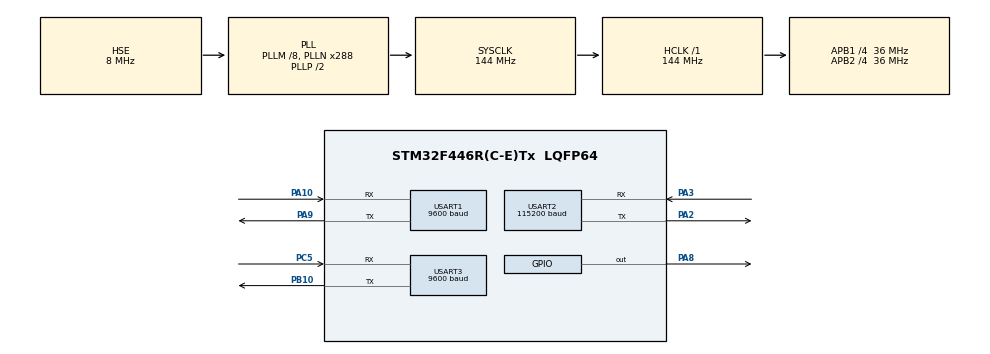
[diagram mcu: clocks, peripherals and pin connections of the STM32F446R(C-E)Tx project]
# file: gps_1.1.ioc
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Mcu.Family=STM32F4
Mcu.Name=STM32F446R(C-E)Tx
Mcu.Package=LQFP64
NVIC.PriorityGroup=NVIC_PRIORITYGROUP_4
NVIC.USART1_IRQn=true\:0\:0\:false\:true\:true\:1\:true
NVIC.USART2_IRQn=true\:0\:0\:false\:true\:true\:2\:true
NVIC.USART3_IRQn=true\:0\:0\:false\:true\:true\:3\:true
PA10.Mode=Asynchronous
PA10.Signal=USART1_RX
PA2.Mode=Asynchronous
PA2.Signal=USART2_TX
PA3.Mode=Asynchronous
PA3.Signal=USART2_RX
PA8.Signal=GPIO_Output
PA9.Mode=Asynchronous
PA9.Signal=USART1_TX
PB10.Mode=Asynchronous
PB10.Signal=USART3_TX
PC5.Mode=Asynchronous
PC5.Signal=USART3_RX
PH0-OSC_IN.Mode=HSE-External-Clock-Source
PH0-OSC_IN.Signal=RCC_OSC_IN
PH1-OSC_OUT.Mode=HSE-External-Clock-Source
PH1-OSC_OUT.Signal=RCC_OSC_OUT
ProjectManager.HeapSize=0x200
ProjectManager.StackSize=0x400
ProjectManager.TargetToolchain=SW4STM32
RCC.AHBFreq_Value=144000000
RCC.APB1CLKDivider=RCC_HCLK_DIV4
RCC.APB1Freq_Value=36000000
RCC.APB1TimFreq_Value=72000000
RCC.APB2CLKDivider=RCC_HCLK_DIV4
RCC.APB2Freq_Value=36000000
RCC.APB2TimFreq_Value=72000000
RCC.CortexFreq_Value=144000000
RCC.HCLKFreq_Value=144000000
RCC.HSE_VALUE=8000000
RCC.PLLM=8
RCC.PLLN=288
RCC.PLLSourceVirtual=RCC_PLLSOURCE_HSE
RCC.SYSCLKFreq_VALUE=144000000
RCC.SYSCLKSource=RCC_SYSCLKSOURCE_PLLCLK
RCC.USBFreq_Value=144000000
RCC.VCOOutputFreq_Value=288000000
USART1.BaudRate=9600
USART1.VirtualMode=VM_ASYNC
USART2.BaudRate=115200
USART2.VirtualMode=VM_ASYNC
USART3.BaudRate=9600
USART3.VirtualMode=VM_ASYNC
board=custom

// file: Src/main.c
/**
  ******************************************************************************
  * @file           : main.c
  * @brief          : Main program body
  ******************************************************************************
  ** This notice applies to any and all portions of this file
  * that are not between comment pairs USER CODE BEGIN and
  * USER CODE END. Other portions of this file, whether
  * inserted by the user or by software development tools
  * are owned by their respective copyright owners.
  *
  * COPYRIGHT(c) 2018 STMicroelectronics
  *
  * Redistribution and use in source and binary forms, with or without modification,
  * are permitted provided that the following conditions are met:
  *   1. Redistributions of source code must retain the above copyright notice,
  *      this list of conditions and the following disclaimer.
  *   2. Redistributions in binary form must reproduce the above copyright notice,
  *      this list of conditions and the following disclaimer in the documentation
  *      and/or other materials provided with the distribution.
  *   3. Neither the name of STMicroelectronics nor the names of its contributors
  *      may be used to endorse or promote products derived from this software
  *      without specific prior written permission.
  *
  * THIS SOFTWARE IS PROVIDED BY THE COPYRIGHT HOLDERS AND CONTRIBUTORS "AS IS"
  * AND ANY EXPRESS OR IMPLIED WARRANTIES, INCLUDING, BUT NOT LIMITED TO, THE
  * IMPLIED WARRANTIES OF MERCHANTABILITY AND FITNESS FOR A PARTICULAR PURPOSE ARE
  * DISCLAIMED. IN NO EVENT SHALL THE COPYRIGHT HOLDER OR CONTRIBUTORS BE LIABLE
  * FOR ANY DIRECT, INDIRECT, INCIDENTAL, SPECIAL, EXEMPLARY, OR CONSEQUENTIAL
  * DAMAGES (INCLUDING, BUT NOT LIMITED TO, PROCUREMENT OF SUBSTITUTE GOODS OR
  * SERVICES; LOSS OF USE, DATA, OR PROFITS; OR BUSINESS INTERRUPTION) HOWEVER
  * CAUSED AND ON ANY THEORY OF LIABILITY, WHETHER IN CONTRACT, STRICT LIABILITY,
  * OR TORT (INCLUDING NEGLIGENCE OR OTHERWISE) ARISING IN ANY WAY OUT OF THE USE
  * OF THIS SOFTWARE, EVEN IF ADVISED OF THE POSSIBILITY OF SUCH DAMAGE.
  *
  ******************************************************************************
  */
#include "main.h"
#include "stm32f4xx_hal.h"

/* USER CODE BEGIN Includes */
#include "function.h"
#include "string.h"
//#include "gps.h"
#include "Eagle_TRT.h"
/* USER CODE END Includes */

UART_HandleTypeDef huart1;
UART_HandleTypeDef huart2;
UART_HandleTypeDef huart3;

/* USER CODE BEGIN PV */
/* Private variables ---------------------------------------------------------*/
gps_struct g;
int ok=0;
/* USER CODE END PV */

void SystemClock_Config(void);
static void MX_GPIO_Init(void);
static void MX_USART1_UART_Init(void);
static void MX_USART2_UART_Init(void);
static void MX_USART3_UART_Init(void);
static void MX_NVIC_Init(void);

/* USER CODE BEGIN PFP */
/* Private function prototypes -----------------------------------------------*/

/* USER CODE END PFP */

/* USER CODE BEGIN 0 */

//GPS-->> Board
//RX -->> D2 = PA10
//TX -->> D8 = PA9

/* USER CODE END 0 */

int main(void)
{

  /* MCU Configuration----------------------------------------------------------*/

  /* Reset of all peripherals, Initializes the Flash interface and the Systick. */
  HAL_Init();

  /* Configure the system clock */
  SystemClock_Config();

  /* Initialize all configured peripherals */
  MX_GPIO_Init();
  MX_USART1_UART_Init();
  MX_USART2_UART_Init();
  MX_USART3_UART_Init();

  /* Initialize interrupts */
  MX_NVIC_Init();
  /* USER CODE BEGIN 2 */
  print("il programma sta iniziando...");
  HAL_Delay(1000);
  gps_init(&huart1,&g);
  /* USER CODE END 2 */

  /* Infinite loop */
  /* USER CODE BEGIN WHILE */
  while (1)
  {
	  /*
	if(ok==1){
		print_it(&huart2,g.time);
		print_it(&huart2," ");
		print_it(&huart2,g.latitude);
		print_it(&huart2," ");
		print_it(&huart2,g.longitude);
		print_it(&huart2," ");
		print_it(&huart2,g.altitude);
		print_it(&huart2," ");
		print_it(&huart2,g.speed);
		print_it(&huart2,"\r\n");
		ok=0;
	}*/

  /* USER CODE END WHILE */

  }

}

void SystemClock_Config(void)
{

  RCC_OscInitTypeDef RCC_OscInitStruct;
  RCC_ClkInitTypeDef RCC_ClkInitStruct;

    /**Configure the main internal regulator output voltage
    */
  __HAL_RCC_PWR_CLK_ENABLE();

  __HAL_PWR_VOLTAGESCALING_CONFIG(PWR_REGULATOR_VOLTAGE_SCALE1);

    /**Initializes the CPU, AHB and APB busses clocks
    */
  RCC_OscInitStruct.OscillatorType = RCC_OSCILLATORTYPE_HSE;
  RCC_OscInitStruct.HSEState = RCC_HSE_BYPASS;
  RCC_OscInitStruct.PLL.PLLState = RCC_PLL_ON;
  RCC_OscInitStruct.PLL.PLLSource = RCC_PLLSOURCE_HSE;
  RCC_OscInitStruct.PLL.PLLM = 8;
  RCC_OscInitStruct.PLL.PLLN = 288;
  RCC_OscInitStruct.PLL.PLLP = RCC_PLLP_DIV2;
  RCC_OscInitStruct.PLL.PLLQ = 2;
  RCC_OscInitStruct.PLL.PLLR = 2;
  if (HAL_RCC_OscConfig(&RCC_OscInitStruct) != HAL_OK)
  {
    _Error_Handler(__FILE__, __LINE__);
  }

    /**Initializes the CPU, AHB and APB busses clocks
    */
  RCC_ClkInitStruct.ClockType = RCC_CLOCKTYPE_HCLK|RCC_CLOCKTYPE_SYSCLK
                              |RCC_CLOCKTYPE_PCLK1|RCC_CLOCKTYPE_PCLK2;
  RCC_ClkInitStruct.SYSCLKSource = RCC_SYSCLKSOURCE_PLLCLK;
  RCC_ClkInitStruct.AHBCLKDivider = RCC_SYSCLK_DIV1;
  RCC_ClkInitStruct.APB1CLKDivider = RCC_HCLK_DIV4;
  RCC_ClkInitStruct.APB2CLKDivider = RCC_HCLK_DIV4;

  if (HAL_RCC_ClockConfig(&RCC_ClkInitStruct, FLASH_LATENCY_4) != HAL_OK)
  {
    _Error_Handler(__FILE__, __LINE__);
  }

    /**Configure the Systick interrupt time
    */
  HAL_SYSTICK_Config(HAL_RCC_GetHCLKFreq()/1000);

    /**Configure the Systick
    */
  HAL_SYSTICK_CLKSourceConfig(SYSTICK_CLKSOURCE_HCLK);

  /* SysTick_IRQn interrupt configuration */
  HAL_NVIC_SetPriority(SysTick_IRQn, 0, 0);
}

/**
  * @brief NVIC Configuration.
  * @retval None
  */
static void MX_NVIC_Init(void)
{
  /* USART1_IRQn interrupt configuration */
  HAL_NVIC_SetPriority(USART1_IRQn, 0, 0);
  HAL_NVIC_EnableIRQ(USART1_IRQn);
  /* USART2_IRQn interrupt configuration */
  HAL_NVIC_SetPriority(USART2_IRQn, 0, 0);
  HAL_NVIC_EnableIRQ(USART2_IRQn);
  /* USART3_IRQn interrupt configuration */
  HAL_NVIC_SetPriority(USART3_IRQn, 0, 0);
  HAL_NVIC_EnableIRQ(USART3_IRQn);
}

/* USART1 init function */
static void MX_USART1_UART_Init(void)
{

  huart1.Instance = USART1;
  huart1.Init.BaudRate = 9600;
  huart1.Init.WordLength = UART_WORDLENGTH_8B;
  huart1.Init.StopBits = UART_STOPBITS_1;
  huart1.Init.Parity = UART_PARITY_NONE;
  huart1.Init.Mode = UART_MODE_TX_RX;
  huart1.Init.HwFlowCtl = UART_HWCONTROL_NONE;
  huart1.Init.OverSampling = UART_OVERSAMPLING_16;
  if (HAL_UART_Init(&huart1) != HAL_OK)
  {
    _Error_Handler(__FILE__, __LINE__);
  }

}

/* USART2 init function */
static void MX_USART2_UART_Init(void)
{

  huart2.Instance = USART2;
  huart2.Init.BaudRate = 115200;
  huart2.Init.WordLength = UART_WORDLENGTH_8B;
  huart2.Init.StopBits = UART_STOPBITS_1;
  huart2.Init.Parity = UART_PARITY_NONE;
  huart2.Init.Mode = UART_MODE_TX_RX;
  huart2.Init.HwFlowCtl = UART_HWCONTROL_NONE;
  huart2.Init.OverSampling = UART_OVERSAMPLING_16;
  if (HAL_UART_Init(&huart2) != HAL_OK)
  {
    _Error_Handler(__FILE__, __LINE__);
  }

}

/* USART3 init function */
static void MX_USART3_UART_Init(void)
{

  huart3.Instance = USART3;
  huart3.Init.BaudRate = 9600;
  huart3.Init.WordLength = UART_WORDLENGTH_8B;
  huart3.Init.StopBits = UART_STOPBITS_1;
  huart3.Init.Parity = UART_PARITY_NONE;
  huart3.Init.Mode = UART_MODE_TX_RX;
  huart3.Init.HwFlowCtl = UART_HWCONTROL_NONE;
  huart3.Init.OverSampling = UART_OVERSAMPLING_16;
  if (HAL_UART_Init(&huart3) != HAL_OK)
  {
    _Error_Handler(__FILE__, __LINE__);
  }

}

/** Configure pins as
        * Analog
        * Input
        * Output
        * EVENT_OUT
        * EXTI
*/
static void MX_GPIO_Init(void)
{

  GPIO_InitTypeDef GPIO_InitStruct;

  /* GPIO Ports Clock Enable */
  __HAL_RCC_GPIOH_CLK_ENABLE();
  __HAL_RCC_GPIOA_CLK_ENABLE();
  __HAL_RCC_GPIOC_CLK_ENABLE();
  __HAL_RCC_GPIOB_CLK_ENABLE();

  /*Configure GPIO pin Output Level */
  HAL_GPIO_WritePin(GPIOA, GPIO_PIN_8, GPIO_PIN_RESET);

  /*Configure GPIO pin : PA8 */
  GPIO_InitStruct.Pin = GPIO_PIN_8;
  GPIO_InitStruct.Mode = GPIO_MODE_OUTPUT_PP;
  GPIO_InitStruct.Pull = GPIO_NOPULL;
  GPIO_InitStruct.Speed = GPIO_SPEED_FREQ_LOW;
  HAL_GPIO_Init(GPIOA, &GPIO_InitStruct);

}

/* USER CODE BEGIN 4 */
void HAL_UART_ErrorCallback(UART_HandleTypeDef *huart){
}

void HAL_UART_RxCpltCallback(UART_HandleTypeDef *huart){
	gps_read_it(huart,&g);

}
void HAL_UART_TxCpltCallback(UART_HandleTypeDef *huart){
	PRINT_INTERRUPT(huart);
}
/* USER CODE END 4 */

void _Error_Handler(char *file, int line)
{
  while(1)
  {
  }
}

/************************ (C) COPYRIGHT STMicroelectronics *****END OF FILE****/
